VERSION ""

BS_:

BU_:

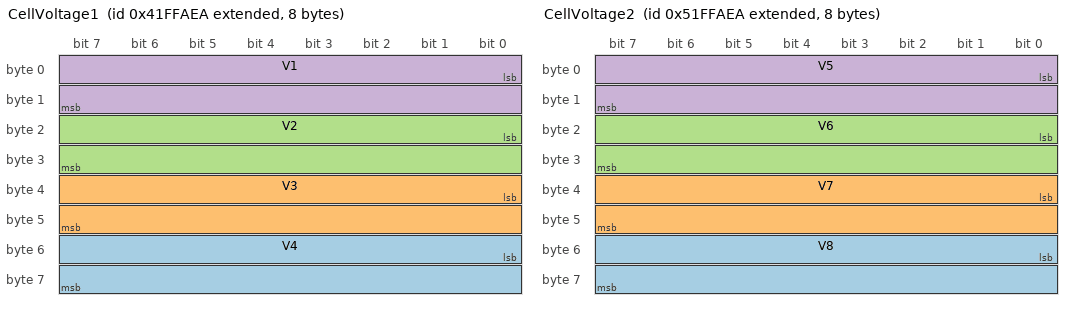
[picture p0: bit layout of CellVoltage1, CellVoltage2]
BO_ 2216688362 CellVoltage1: 8 Vector__XXX
 SG_ V4 : 48|16@1+ (1,0) [0|65535] "Volts" Vector__XXX
 SG_ V3 : 32|16@1+ (1,0) [0|65535] "Volts" Vector__XXX
 SG_ V2 : 16|16@1+ (1,0) [0|65535] "Volts" Vector__XXX
 SG_ V1 : 0|16@1+ (1,0) [0|65535] "Volts" Vector__XXX

BO_ 2233465578 CellVoltage2: 8 Vector__XXX
 SG_ V8 : 48|16@1+ (1,0) [0|65535] "Volts" Vector__XXX
 SG_ V7 : 32|16@1+ (1,0) [0|65535] "Volts" Vector__XXX
 SG_ V6 : 16|16@1+ (1,0) [0|65535] "Volts" Vector__XXX
 SG_ V5 : 0|16@1+ (1,0) [0|65535] "Volts" Vector__XXX

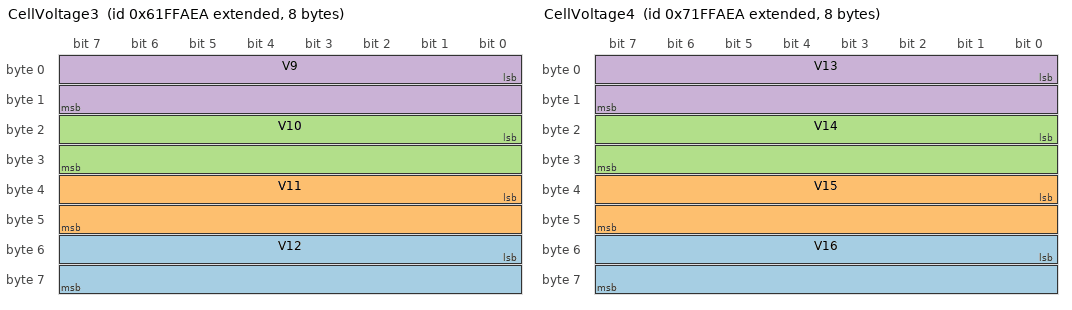
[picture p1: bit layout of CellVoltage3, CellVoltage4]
BO_ 2250242794 CellVoltage3: 8 Vector__XXX
 SG_ V12 : 48|16@1+ (1,0) [0|65535] "Volts" Vector__XXX
 SG_ V11 : 32|16@1+ (1,0) [0|65535] "Volts" Vector__XXX
 SG_ V10 : 16|16@1+ (1,0) [0|65535] "Volts" Vector__XXX
 SG_ V9 : 0|16@1+ (1,0) [0|65535] "Volts" Vector__XXX

BO_ 2267020010 CellVoltage4: 8 Vector__XXX
 SG_ V16 : 48|16@1+ (1,0) [0|65535] "Volts" Vector__XXX
 SG_ V15 : 32|16@1+ (1,0) [0|65535] "Volts" Vector__XXX
 SG_ V14 : 16|16@1+ (1,0) [0|65535] "Volts" Vector__XXX
 SG_ V13 : 0|16@1+ (1,0) [0|65535] "Volts" Vector__XXX

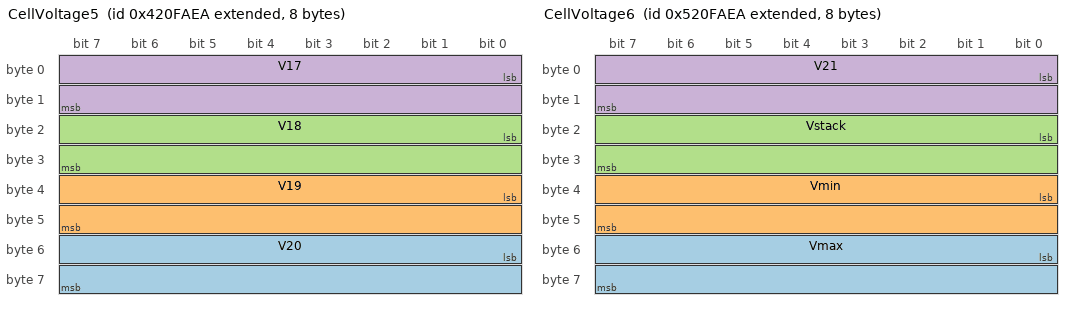
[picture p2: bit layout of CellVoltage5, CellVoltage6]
BO_ 2216753898 CellVoltage5: 8 Vector__XXX
 SG_ V20 : 48|16@1+ (1,0) [0|65535] "Volts" Vector__XXX
 SG_ V19 : 32|16@1+ (1,0) [0|65535] "Volts" Vector__XXX
 SG_ V18 : 16|16@1+ (1,0) [0|65535] "Volts" Vector__XXX
 SG_ V17 : 0|16@1+ (1,0) [0|65535] "Volts" Vector__XXX

BO_ 2233531114 CellVoltage6: 8 Vector__XXX
 SG_ Vmax : 48|16@1+ (1,0) [0|65535] "Volts" Vector__XXX
 SG_ Vmin : 32|16@1+ (1,0) [0|65535] "Volts" Vector__XXX
 SG_ Vstack : 16|16@1+ (1,0) [0|65535] "Volts" Vector__XXX
 SG_ V21 : 0|16@1+ (1,0) [0|65535] "Volts" Vector__XXX

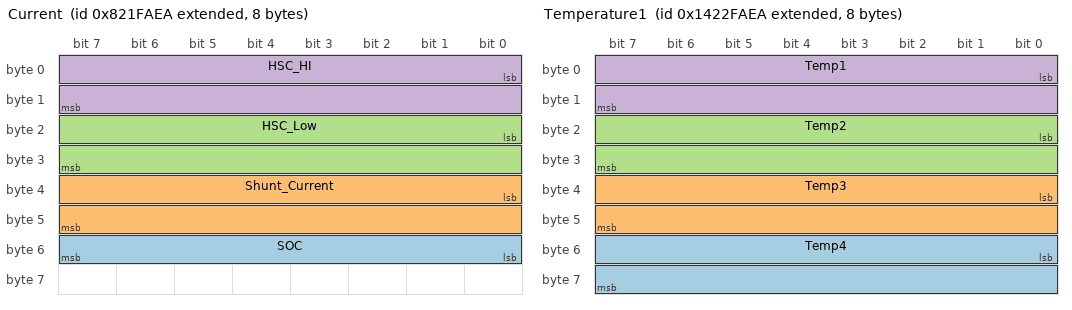
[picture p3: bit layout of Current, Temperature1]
BO_ 2283928298 Current: 8 Vector__XXX
 SG_ SOC : 48|8@1+ (1,0) [0|255] "" Vector__XXX
 SG_ Shunt_Current : 32|16@1- (1,0) [-32768|32767] "Amps" Vector__XXX
 SG_ HSC_Low : 16|16@1- (1,0) [-32768|32767] "Amps" Vector__XXX
 SG_ HSC_HI : 0|16@1- (1,0) [-32768|32767] "Amps" Vector__XXX

BO_ 2485320426 Temperature1: 8 Vector__XXX
 SG_ Temp4 : 48|16@1+ (1,0) [0|65535] "DegC" Vector__XXX
 SG_ Temp3 : 32|16@1+ (1,0) [0|65535] "DegC" Vector__XXX
 SG_ Temp2 : 16|16@1+ (1,0) [0|65535] "DegC" Vector__XXX
 SG_ Temp1 : 0|16@1+ (1,0) [0|65535] "DegC" Vector__XXX

BO_ 2351168234 State: 8 Vector__XXX
 SG_ BalancingstatusC21 : 44|1@1- (1,0) [0|1] "" Vector__XXX
 SG_ BalancingstatusC20 : 43|1@1- (1,0) [0|1] "" Vector__XXX
 SG_ BalancingstatusC19 : 42|1@1- (1,0) [0|1] "" Vector__XXX
 SG_ BalancingstatusC18 : 41|1@1- (1,0) [0|1] "" Vector__XXX
 SG_ BalancingstatusC17 : 40|1@1- (1,0) [0|1] "" Vector__XXX
 SG_ BalancingstatusC16 : 39|1@1- (1,0) [0|1] "" Vector__XXX
 SG_ BalancingstatusC15 : 38|1@1- (1,0) [0|1] "" Vector__XXX
 SG_ BalancingstatusC14 : 37|1@1- (1,0) [0|1] "" Vector__XXX
 SG_ BalancingstatusC13 : 36|1@1- (1,0) [0|1] "" Vector__XXX
 SG_ BalancingstatusC12 : 35|1@1- (1,0) [0|1] "" Vector__XXX
 SG_ BalancingstatusC11 : 34|1@1- (1,0) [0|1] "" Vector__XXX
 SG_ BalancingstatusC10 : 33|1@1- (1,0) [0|1] "" Vector__XXX
 SG_ BalancingstatusC9 : 32|1@1- (1,0) [0|1] "" Vector__XXX
 SG_ BalancingstatusC8 : 31|1@1- (1,0) [0|1] "" Vector__XXX
 SG_ BalancingstatusC7 : 30|1@1- (1,0) [0|1] "" Vector__XXX
 SG_ BalancingstatusC6 : 29|1@1- (1,0) [0|1] "" Vector__XXX
 SG_ BalancingstatusC5 : 28|1@1- (1,0) [0|1] "" Vector__XXX
 SG_ BalancingstatusC4 : 27|1@1- (1,0) [0|1] "" Vector__XXX
 SG_ BalancingstatusC3 : 26|1@1- (1,0) [0|1] "" Vector__XXX
 SG_ BalancingstatusC2 : 25|1@1- (1,0) [0|1] "" Vector__XXX
 SG_ BalancingstatusC1 : 24|1@1- (1,0) [0|1] "" Vector__XXX
 SG_ VehicleState : 16|8@1+ (1,0) [0|255] "" Vector__XXX
 SG_ Ready : 7|1@1- (1,0) [0|1] "" Vector__XXX
 SG_ OverTemp : 4|1@1- (1,0) [0|1] "" Vector__XXX
 SG_ PrechargeFailure : 3|1@1- (1,0) [0|1] "" Vector__XXX
 SG_ OverCurrent : 2|1@1- (1,0) [0|1] "" Vector__XXX
 SG_ Undervoltage : 1|1@1- (1,0) [0|1] "" Vector__XXX
 SG_ OverVoltage : 0|1@1- (1,0) [0|1] "" Vector__XXX

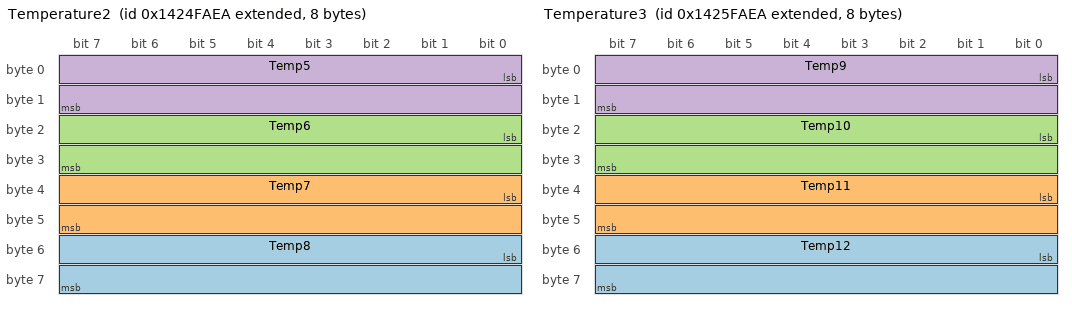
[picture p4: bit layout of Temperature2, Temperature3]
BO_ 2485451498 Temperature2: 8 Vector__XXX
 SG_ Temp8 : 48|16@1+ (1,0) [0|65535] "DegC" Vector__XXX
 SG_ Temp7 : 32|16@1+ (1,0) [0|65535] "DegC" Vector__XXX
 SG_ Temp6 : 16|16@1+ (1,0) [0|65535] "DegC" Vector__XXX
 SG_ Temp5 : 0|16@1+ (1,0) [0|65535] "DegC" Vector__XXX

BO_ 2485517034 Temperature3: 8 Vector__XXX
 SG_ Temp12 : 48|16@1+ (1,0) [0|65535] "DegC" Vector__XXX
 SG_ Temp11 : 32|16@1+ (1,0) [0|65535] "DegC" Vector__XXX
 SG_ Temp10 : 16|16@1+ (1,0) [0|65535] "DegC" Vector__XXX
 SG_ Temp9 : 0|16@1+ (1,0) [0|65535] "DegC" Vector__XXX

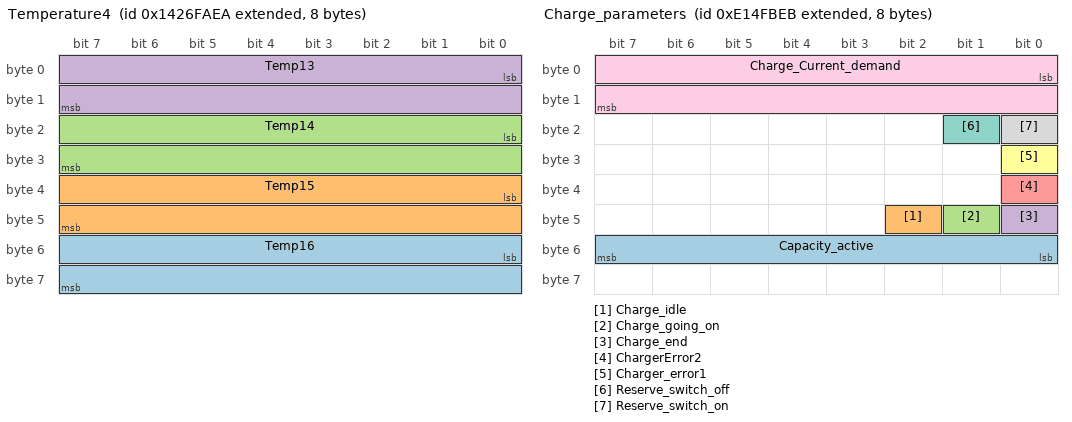
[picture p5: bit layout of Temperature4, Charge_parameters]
BO_ 2485582570 Temperature4: 8 Vector__XXX
 SG_ Temp16 : 48|16@1+ (1,0) [0|65535] "DegC" Vector__XXX
 SG_ Temp15 : 32|16@1+ (1,0) [0|65535] "DegC" Vector__XXX
 SG_ Temp14 : 16|16@1+ (1,0) [0|65535] "DegC" Vector__XXX
 SG_ Temp13 : 0|16@1+ (1,0) [0|65535] "DegC" Vector__XXX

BO_ 2383739883 Charge_parameters: 8 Vector__XXX
 SG_ Capacity_active : 48|8@1+ (1,0) [0|255] "ah" Vector__XXX
 SG_ Charge_idle : 42|1@1- (1,0) [0|1] "" Vector__XXX
 SG_ Charge_going_on : 41|1@1- (1,0) [0|1] "" Vector__XXX
 SG_ Charge_end : 40|1@1- (1,0) [0|1] "" Vector__XXX
 SG_ ChargerError2 : 32|1@1- (1,0) [0|1] "" Vector__XXX
 SG_ Charger_error1 : 24|1@1- (1,0) [0|1] "" Vector__XXX
 SG_ Reserve_switch_off : 17|1@1- (1,0) [0|1] "None" Vector__XXX
 SG_ Reserve_switch_on : 16|1@1- (1,0) [0|1] "None" Vector__XXX
 SG_ Charge_Current_demand : 0|16@1+ (1,0) [0|65535] "amp" Vector__XXX

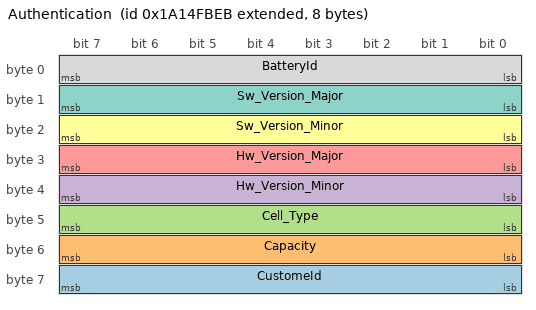
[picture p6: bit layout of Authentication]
BO_ 2585066475 Authentication: 8 Vector__XXX
 SG_ CustomeId : 56|8@1+ (1,0) [0|255] "None" Vector__XXX
 SG_ Capacity : 48|8@1+ (1,0) [0|255] "Ah" Vector__XXX
 SG_ Cell_Type : 40|8@1+ (1,0) [0|255] "None" Vector__XXX
 SG_ Hw_Version_Minor : 32|8@1+ (1,0) [0|255] "None" Vector__XXX
 SG_ Hw_Version_Major : 24|8@1+ (1,0) [0|255] "None" Vector__XXX
 SG_ Sw_Version_Minor : 16|8@1+ (1,0) [0|255] "None" Vector__XXX
 SG_ Sw_Version_Major : 8|8@1+ (1,0) [0|255] "None" Vector__XXX
 SG_ BatteryId : 0|8@1+ (1,0) [0|255] "None" Vector__XXX
